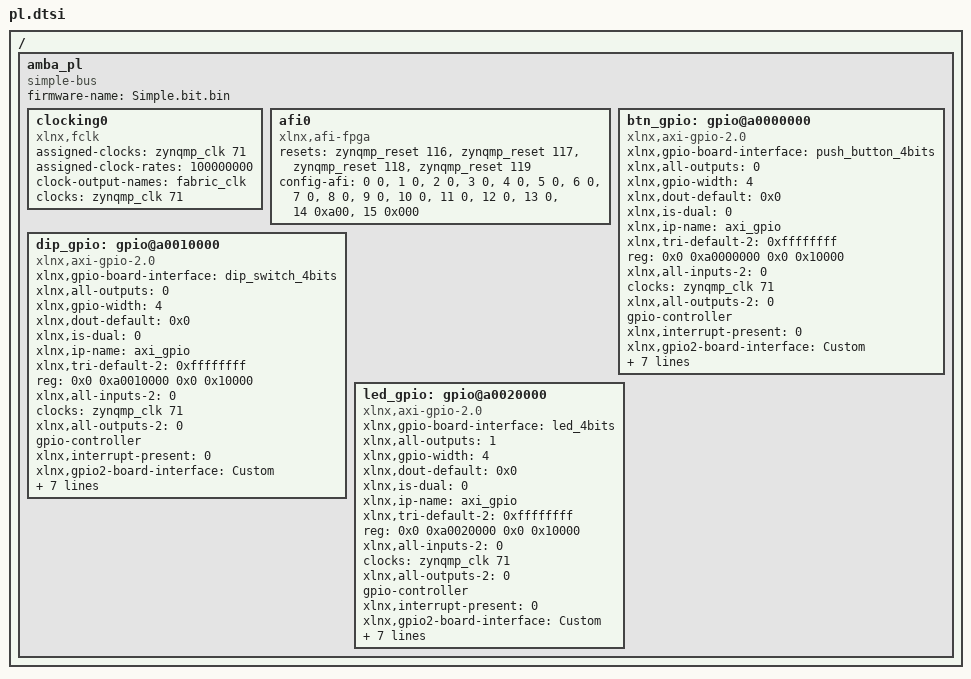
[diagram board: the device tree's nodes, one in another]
/ {
	amba_pl: amba_pl {
		ranges;
		compatible = "simple-bus";
		#address-cells = <2>;
		#size-cells = <2>;
		firmware-name = "Simple.bit.bin";
		clocking0: clocking0 {
			compatible = "xlnx,fclk";
			status = "okay";
			assigned-clocks = <&zynqmp_clk 71>;
			assigned-clock-rates = <100000000>;
			#clock-cells = <0>;
			clock-output-names = "fabric_clk";
			clocks = <&zynqmp_clk 71>;
		};
		afi0: afi0 {
			status = "okay";
			compatible = "xlnx,afi-fpga";
			resets = <&zynqmp_reset 116>, <&zynqmp_reset 117>, <&zynqmp_reset 118>, <&zynqmp_reset 119>;
			config-afi = < 0 0>, <1 0>, <2 0>, <3 0>, <4 0>, <5 0>, <6 0>, <7 0>, <8 0>, <9 0>, <10 0>, <11 0>, <12 0>, <13 0>, <14 0xa00>, <15 0x000>;
		};
		btn_gpio: gpio@a0000000 {
			xlnx,gpio-board-interface = "push_button_4bits";
			compatible = "xlnx,axi-gpio-2.0" , "xlnx,xps-gpio-1.00.a";
			xlnx,all-outputs = <0>;
			#gpio-cells = <2>;
			xlnx,gpio-width = <4>;
			xlnx,dout-default = <0x0>;
			xlnx,is-dual = <0>;
			xlnx,ip-name = "axi_gpio";
			xlnx,tri-default-2 = <0xffffffff>;
			reg = <0x0 0xa0000000 0x0 0x10000>;
			xlnx,all-inputs-2 = <0>;
			clocks = <&zynqmp_clk 71>;
			xlnx,all-outputs-2 = <0>;
			gpio-controller;
			xlnx,interrupt-present = <0>;
			xlnx,gpio2-board-interface = "Custom";
			xlnx,edk-iptype = "PERIPHERAL";
			xlnx,dout-default-2 = <0x0>;
			status = "okay";
			xlnx,gpio2-width = <32>;
			clock-names = "s_axi_aclk";
			xlnx,use-board-flow;
			xlnx,tri-default = <0xffffffff>;
			xlnx,name = "btn_gpio";
			xlnx,all-inputs = <1>;
		};
		dip_gpio: gpio@a0010000 {
			xlnx,gpio-board-interface = "dip_switch_4bits";
			compatible = "xlnx,axi-gpio-2.0" , "xlnx,xps-gpio-1.00.a";
			xlnx,all-outputs = <0>;
			#gpio-cells = <2>;
			xlnx,gpio-width = <4>;
			xlnx,dout-default = <0x0>;
			xlnx,is-dual = <0>;
			xlnx,ip-name = "axi_gpio";
			xlnx,tri-default-2 = <0xffffffff>;
			reg = <0x0 0xa0010000 0x0 0x10000>;
			xlnx,all-inputs-2 = <0>;
			clocks = <&zynqmp_clk 71>;
			xlnx,all-outputs-2 = <0>;
			gpio-controller;
			xlnx,interrupt-present = <0>;
			xlnx,gpio2-board-interface = "Custom";
			xlnx,edk-iptype = "PERIPHERAL";
			xlnx,dout-default-2 = <0x0>;
			status = "okay";
			xlnx,gpio2-width = <32>;
			clock-names = "s_axi_aclk";
			xlnx,use-board-flow;
			xlnx,tri-default = <0xffffffff>;
			xlnx,name = "dip_gpio";
			xlnx,all-inputs = <1>;
		};
		led_gpio: gpio@a0020000 {
			xlnx,gpio-board-interface = "led_4bits";
			compatible = "xlnx,axi-gpio-2.0" , "xlnx,xps-gpio-1.00.a";
			xlnx,all-outputs = <1>;
			#gpio-cells = <2>;
			xlnx,gpio-width = <4>;
			xlnx,dout-default = <0x0>;
			xlnx,is-dual = <0>;
			xlnx,ip-name = "axi_gpio";
			xlnx,tri-default-2 = <0xffffffff>;
			reg = <0x0 0xa0020000 0x0 0x10000>;
			xlnx,all-inputs-2 = <0>;
			clocks = <&zynqmp_clk 71>;
			xlnx,all-outputs-2 = <0>;
			gpio-controller;
			xlnx,interrupt-present = <0>;
			xlnx,gpio2-board-interface = "Custom";
			xlnx,edk-iptype = "PERIPHERAL";
			xlnx,dout-default-2 = <0x0>;
			status = "okay";
			xlnx,gpio2-width = <32>;
			clock-names = "s_axi_aclk";
			xlnx,use-board-flow;
			xlnx,tri-default = <0xffffffff>;
			xlnx,name = "led_gpio";
			xlnx,all-inputs = <0>;
		};
	};
};
